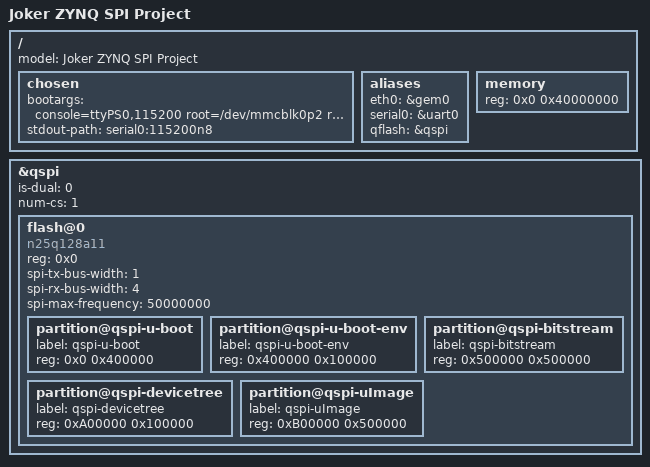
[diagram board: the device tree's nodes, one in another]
/dts-v1/;
#include "zynq-7000.dtsi"
#include "pcw.dtsi"

/ {
    model = "Joker ZYNQ SPI Project";

    chosen {
        bootargs = "console=ttyPS0,115200 root=/dev/mmcblk0p2 rootwait rw rootfstype=ext4";
        stdout-path = "serial0:115200n8";
    };

    aliases {
        eth0    = &gem0;
        serial0 = &uart0;
        qflash  = &qspi;
    };

    memory {
		device_type = "memory";
		reg = <0x0 0x40000000>;
	};
};

&qspi {
    status = "okay";
    is-dual = <0>;
    num-cs = <1>;

    flash@0 {
        // 128Mb qspi 
        compatible = "n25q128a11";
        reg = <0x0>;
        spi-tx-bus-width = <1>;
        spi-rx-bus-width = <4>;
        spi-max-frequency = <50000000>;
        #address-cells = <1>;
        #size-cells = <1>;

        // 4MB
        partition@qspi-u-boot {
            label = "qspi-u-boot";
            reg = <0x0 0x400000>;
        };
        partition@qspi-u-boot-env {
            label = "qspi-u-boot-env";
            reg = <0x400000 0x100000>;
        };
        partition@qspi-bitstream {
            label = "qspi-bitstream";
            reg = <0x500000 0x500000>;
        };
        partition@qspi-devicetree {
            label = "qspi-devicetree";
            reg = <0xA00000 0x100000>;
        };
        partition@qspi-uImage {
            label = "qspi-uImage";
            reg = <0xB00000 0x500000>;
        };
    };
};
